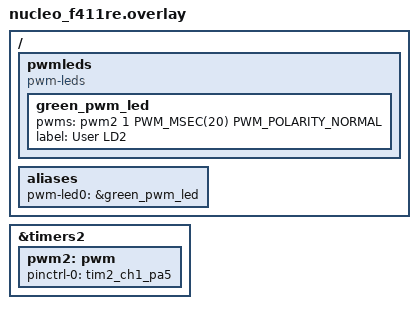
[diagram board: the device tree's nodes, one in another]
/ {
    pwmleds {
        #address-cells = <2>;
        #size-cells = <1>; 

        compatible = "pwm-leds";
        status = "okay";

        green_pwm_led: green_pwm_led {
            pwms = <&pwm2 1 PWM_MSEC(20) PWM_POLARITY_NORMAL>;
            label = "User LD2";
        };
    };

    aliases {
        pwm-led0 = &green_pwm_led;
    };
};

&timers2 {
    status = "okay";

    pwm2: pwm {
        status = "okay";
        pinctrl-0 = <&tim2_ch1_pa5>;
        pinctrl-names = "default";
    };
};

